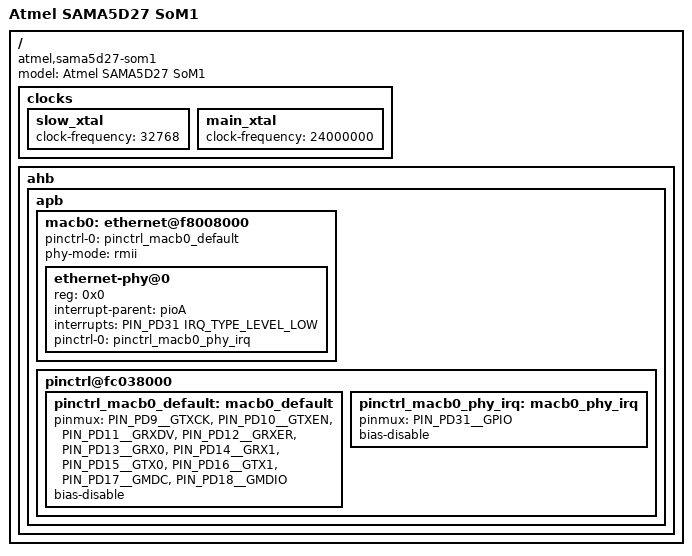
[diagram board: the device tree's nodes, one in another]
// SPDX-License-Identifier: (GPL-2.0+ OR MIT)
/*
 * at91-sama5d27_som1.dtsi - Device Tree file for SAMA5D27 SoM1 board
 *
 *  Copyright (c) 2017, Microchip Technology Inc.
 *                2017 Cristian Birsan <cristian.birsan@microchip.com>
 *                2017 Claudiu Beznea <claudiu.beznea@microchip.com>
 */
#include "sama5d2.dtsi"
#include "sama5d2-pinfunc.h"

/ {
	model = "Atmel SAMA5D27 SoM1";
	compatible = "atmel,sama5d27-som1", "atmel,sama5d27", "atmel,sama5d2", "atmel,sama5";

	clocks {
		slow_xtal {
			clock-frequency = <32768>;
		};

		main_xtal {
			clock-frequency = <24000000>;
		};
	};

	ahb {
		apb {
			macb0: ethernet@f8008000 {
				pinctrl-names = "default";
				pinctrl-0 = <&pinctrl_macb0_default>;
				phy-mode = "rmii";

				ethernet-phy@0 {
					reg = <0x0>;
					interrupt-parent = <&pioA>;
					interrupts = <PIN_PD31 IRQ_TYPE_LEVEL_LOW>;
					pinctrl-names = "default";
					pinctrl-0 = <&pinctrl_macb0_phy_irq>;
				};
			};

			pinctrl@fc038000 {

				pinctrl_macb0_default: macb0_default {
					pinmux = <PIN_PD9__GTXCK>,
						 <PIN_PD10__GTXEN>,
						 <PIN_PD11__GRXDV>,
						 <PIN_PD12__GRXER>,
						 <PIN_PD13__GRX0>,
						 <PIN_PD14__GRX1>,
						 <PIN_PD15__GTX0>,
						 <PIN_PD16__GTX1>,
						 <PIN_PD17__GMDC>,
						 <PIN_PD18__GMDIO>;
					bias-disable;
				};

				pinctrl_macb0_phy_irq: macb0_phy_irq {
					pinmux = <PIN_PD31__GPIO>;
					bias-disable;
				};
			};
		};
	};
};
